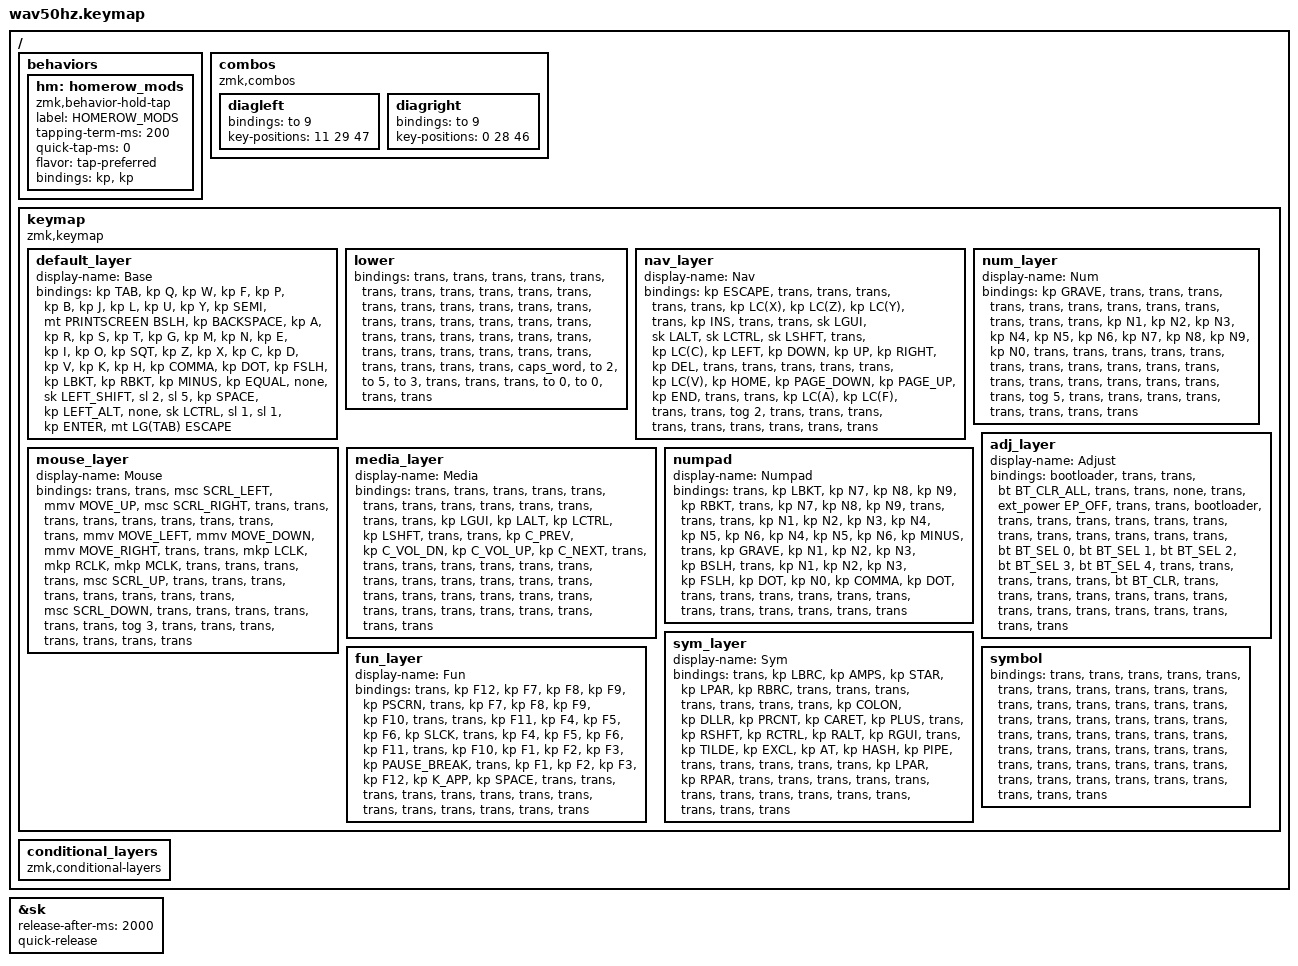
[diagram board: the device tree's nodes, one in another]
#include <dt-bindings/zmk/mouse.h>
#include <behaviors.dtsi>
#include <dt-bindings/zmk/bt.h>
#include <dt-bindings/zmk/ext_power.h>
#include <dt-bindings/zmk/keys.h>
// pointing.h is mainline ZMK (post-PR#2477); petejohanson's fork uses mouse.h above

// Layer Definitions

#define BASE 0
#define NAV 1
#define MOUSE 2
#define MEDIA 3
#define NUM 4
#define SYM 5
#define FUN 6
#define ADJ 7

// Behavior Configuration

&sk {
    release-after-ms = <2000>;
    quick-release;
};

/ {
    behaviors {
        // Home Row Mods: Tap for key, Hold for modifier

        hm: homerow_mods {
            compatible = "zmk,behavior-hold-tap";
            label = "HOMEROW_MODS";
            #binding-cells = <2>;
            tapping-term-ms = <200>;
            quick-tap-ms = <0>;
            flavor = "tap-preferred";
            bindings = <&kp>, <&kp>;
        };
    };

    combos {
        compatible = "zmk,combos";

        diagleft {
            bindings = <&to 9>;
            key-positions = <11 29 47>;
        };

        diagright {
            bindings = <&to 9>;
            key-positions = <0 28 46>;
        };
    };

    keymap {
        compatible = "zmk,keymap";

        default_layer {
            display-name = "Base";
            bindings = <
&kp TAB        &kp Q  &kp W     &kp F     &kp P  &kp B  &kp J  &kp L  &kp U      &kp Y      &kp SEMI  &mt PRINTSCREEN BSLH
&kp BACKSPACE  &kp A  &kp R     &kp S     &kp T  &kp G  &kp M  &kp N  &kp E      &kp I      &kp O     &kp SQT
               &kp Z  &kp X     &kp C     &kp D  &kp V  &kp K  &kp H  &kp COMMA  &kp DOT    &kp FSLH
                      &kp LBKT  &kp RBKT                              &kp MINUS  &kp EQUAL
                                                                                                                              &none      &sk LEFT_SHIFT
                                                                                                                              &sl 2      &sl 5
                                                                                                                              &kp SPACE  &kp LEFT_ALT
                                                                                                                              &none      &sk LCTRL
                                                                                                                              &sl 1      &sl 1
                                                                                                                              &kp ENTER  &mt LG(TAB) ESCAPE
            >;
        };

        lower {
            bindings = <
&trans  &trans  &trans  &trans  &trans  &trans  &trans  &trans  &trans  &trans  &trans  &trans
&trans  &trans  &trans  &trans  &trans  &trans  &trans  &trans  &trans  &trans  &trans  &trans
        &trans  &trans  &trans  &trans  &trans  &trans  &trans  &trans  &trans  &trans
                &trans  &trans                                  &trans  &trans
                                                                                                  &trans  &caps_word
                                                                                                  &to 2   &to 5
                                                                                                  &to 3   &trans
                                                                                                  &trans  &trans
                                                                                                  &to 0   &to 0
                                                                                                  &trans  &trans
            >;
        };

        nav_layer {
            display-name = "Nav";
            bindings = <
&kp ESCAPE  &trans    &trans    &trans     &trans     &trans  &kp LC(X)  &kp LC(Z)  &kp LC(Y)      &trans       &kp INS    &trans
&trans      &sk LGUI  &sk LALT  &sk LCTRL  &sk LSHFT  &trans  &kp LC(C)  &kp LEFT   &kp DOWN       &kp UP       &kp RIGHT  &kp DEL
            &trans    &trans    &trans     &trans     &trans  &kp LC(V)  &kp HOME   &kp PAGE_DOWN  &kp PAGE_UP  &kp END
                      &trans    &trans                                              &kp LC(A)      &kp LC(F)
                                                                                                                                      &trans  &trans
                                                                                                                                      &tog 2  &trans
                                                                                                                                      &trans  &trans
                                                                                                                                      &trans  &trans
                                                                                                                                      &trans  &trans
                                                                                                                                      &trans  &trans
            >;
        };

        mouse_layer {
            display-name = "Mouse";
            bindings = <
&trans  &trans  &msc SCRL_LEFT  &mmv MOVE_UP    &msc SCRL_RIGHT  &trans  &trans  &trans     &trans     &trans     &trans  &trans
&trans  &trans  &mmv MOVE_LEFT  &mmv MOVE_DOWN  &mmv MOVE_RIGHT  &trans  &trans  &mkp LCLK  &mkp RCLK  &mkp MCLK  &trans  &trans
        &trans  &trans          &msc SCRL_UP    &trans           &trans  &trans  &trans     &trans     &trans     &trans
                &trans          &msc SCRL_DOWN                                              &trans     &trans
                                                                                                                                    &trans  &trans
                                                                                                                                    &trans  &trans
                                                                                                                                    &tog 3  &trans
                                                                                                                                    &trans  &trans
                                                                                                                                    &trans  &trans
                                                                                                                                    &trans  &trans
            >;
        };

        media_layer {
            display-name = "Media";
            bindings = <
&trans  &trans    &trans    &trans     &trans     &trans  &trans  &trans      &trans        &trans        &trans      &trans
&trans  &kp LGUI  &kp LALT  &kp LCTRL  &kp LSHFT  &trans  &trans  &kp C_PREV  &kp C_VOL_DN  &kp C_VOL_UP  &kp C_NEXT  &trans
        &trans    &trans    &trans     &trans     &trans  &trans  &trans      &trans        &trans        &trans
                  &trans    &trans                                            &trans        &trans
                                                                                                                                &trans  &trans
                                                                                                                                &trans  &trans
                                                                                                                                &trans  &trans
                                                                                                                                &trans  &trans
                                                                                                                                &trans  &trans
                                                                                                                                &trans  &trans
            >;
        };

        num_layer {
            display-name = "Num";
            bindings = <
&kp GRAVE  &trans  &trans  &trans  &trans  &trans  &trans  &trans  &trans  &trans  &trans  &trans
&trans     &kp N1  &kp N2  &kp N3  &kp N4  &kp N5  &kp N6  &kp N7  &kp N8  &kp N9  &kp N0  &trans
           &trans  &trans  &trans  &trans  &trans  &trans  &trans  &trans  &trans  &trans
                   &trans  &trans                                  &trans  &trans
                                                                                                     &trans  &trans
                                                                                                     &trans  &tog 5
                                                                                                     &trans  &trans
                                                                                                     &trans  &trans
                                                                                                     &trans  &trans
                                                                                                     &trans  &trans
            >;
        };

        numpad {
            display-name = "Numpad";
            bindings = <
&trans  &kp LBKT   &kp N7   &kp N8  &kp N9  &kp RBKT  &trans  &kp N7  &kp N8     &kp N9   &trans     &trans
&trans  &kp N1     &kp N2   &kp N3  &kp N4  &kp N5    &kp N6  &kp N4  &kp N5     &kp N6   &kp MINUS  &trans
        &kp GRAVE  &kp N1   &kp N2  &kp N3  &kp BSLH  &trans  &kp N1  &kp N2     &kp N3   &kp FSLH
                   &kp DOT  &kp N0                                    &kp COMMA  &kp DOT
                                                                                                               &trans  &trans
                                                                                                               &trans  &trans
                                                                                                               &trans  &trans
                                                                                                               &trans  &trans
                                                                                                               &trans  &trans
                                                                                                               &trans  &trans
            >;
        };

        sym_layer {
            display-name = "Sym";
            bindings = <
&trans  &kp LBRC   &kp AMPS  &kp STAR   &kp LPAR   &kp RBRC  &trans  &trans     &trans     &trans    &trans    &trans
&trans  &kp COLON  &kp DLLR  &kp PRCNT  &kp CARET  &kp PLUS  &trans  &kp RSHFT  &kp RCTRL  &kp RALT  &kp RGUI  &trans
        &kp TILDE  &kp EXCL  &kp AT     &kp HASH   &kp PIPE  &trans  &trans     &trans     &trans    &trans
                   &kp LPAR  &kp RPAR                                           &trans     &trans
                                                                                                                         &trans  &trans
                                                                                                                         &trans  &trans
                                                                                                                         &trans  &trans
                                                                                                                         &trans  &trans
                                                                                                                         &trans  &trans
                                                                                                                         &trans  &trans
            >;
        };

        fun_layer {
            display-name = "Fun";
            bindings = <
&trans  &kp F12  &kp F7     &kp F8     &kp F9  &kp PSCRN        &trans  &kp F7  &kp F8  &kp F9  &kp F10  &trans
&trans  &kp F11  &kp F4     &kp F5     &kp F6  &kp SLCK         &trans  &kp F4  &kp F5  &kp F6  &kp F11  &trans
        &kp F10  &kp F1     &kp F2     &kp F3  &kp PAUSE_BREAK  &trans  &kp F1  &kp F2  &kp F3  &kp F12
                 &kp K_APP  &kp SPACE                                           &trans  &trans
                                                                                                                   &trans  &trans
                                                                                                                   &trans  &trans
                                                                                                                   &trans  &trans
                                                                                                                   &trans  &trans
                                                                                                                   &trans  &trans
                                                                                                                   &trans  &trans
            >;
        };

        adj_layer {
            display-name = "Adjust";
            bindings = <
&bootloader  &trans        &trans        &bt BT_CLR_ALL  &trans        &trans        &none           &trans  &ext_power EP_OFF  &trans  &trans  &bootloader
&trans       &trans        &trans        &trans          &trans        &trans        &trans          &trans  &trans             &trans  &trans  &trans
             &bt BT_SEL 0  &bt BT_SEL 1  &bt BT_SEL 2    &bt BT_SEL 3  &bt BT_SEL 4  &trans          &trans  &trans             &trans  &trans
                           &bt BT_CLR    &trans                                                              &trans             &trans
                                                                                                                                                               &trans  &trans
                                                                                                                                                               &trans  &trans
                                                                                                                                                               &trans  &trans
                                                                                                                                                               &trans  &trans
                                                                                                                                                               &trans  &trans
                                                                                                                                                               &trans  &trans
            >;
        };

        symbol {
            bindings = <
&trans  &trans  &trans  &trans  &trans  &trans  &trans  &trans  &trans  &trans  &trans  &trans
&trans  &trans  &trans  &trans  &trans  &trans  &trans  &trans  &trans  &trans  &trans  &trans
        &trans  &trans  &trans  &trans  &trans  &trans  &trans  &trans  &trans  &trans
                &trans  &trans                                  &trans  &trans
                                                                                                  &trans  &trans
                                                                                                  &trans  &trans
                                                                                                  &trans  &trans
                                                                                                  &trans  &trans
                                                                                                  &trans  &trans
                                                                                                  &trans  &trans
            >;
        };
    };

    conditional_layers { compatible = "zmk,conditional-layers"; };
};
